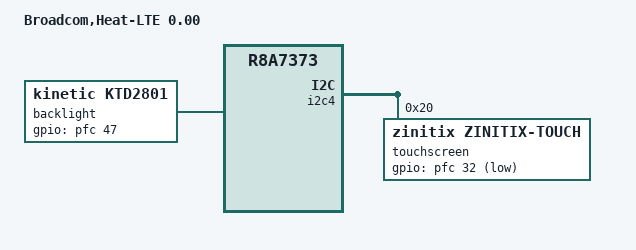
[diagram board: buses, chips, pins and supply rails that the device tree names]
/******************************************************************************/
/*                                                                            */
/* Copyright 2013 Broadcom Corporation                                        */
/*                                                                            */
/* Unless you and Broadcom execute a separate written software license        */
/* agreement governing use of this software, this software is licensed        */
/* to you under the terms of the GNU General Public License version 2         */
/* (the GPL), available at                                                    */
/*                                                                            */
/* http://www.broadcom.com/licenses/GPLv2.php                                 */
/*                                                                            */
/* with the following added to such license:                                  */
/*                                                                            */
/* As a special exception, the copyright holders of this software give        */
/* you permission to link this software with independent modules, and         */
/* to copy and distribute the resulting executable under terms of your        */
/* choice, provided that you also meet, for each linked independent           */
/* module, the terms and conditions of the license of that module.            */
/* An independent module is a module which is not derived from this           */
/* software. The special exception does not apply to any modifications        */
/* of the software.                                                           */
/*                                                                            */
/* Notwithstanding the above, under no circumstances may you combine          */
/* this software in any way with any other Broadcom software provided         */
/* under a license other than the GPL, without Broadcom's express             */
/* prior written consent.                                                     */
/*                                                                            */
/******************************************************************************/

#include "r8a7373-heatlte-common.dtsi"

/{

	model = "Broadcom,Heat-LTE 0.00";

	backlight {
		compatible = "kinetic,ktd2801";
		max-brightness = <255>;
		default-brightness = <143>;
		gpios = <&pfc 47 GPIO_ACTIVE_HIGH>;
	};
};
&i2c4 {
       /* Board code Register the Oled Touch Panel */
       /* This is Non-Oled Touch Panel */
		touchscreen@20 {
		compatible = "zinitix,zinitix-touch";
		reg = <0x20>;
		gpios = <&pfc 32 GPIO_ACTIVE_LOW>;
	};
};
